# H5 register map
Vendor: Allwinner; Series: H5; File version: 0.1
CPU: 0, little endian, MPU, no FPU, 0 interrupt priority bits
Registers are 32-bit, read-write, reset 0x0 unless marked. A register's access mark holds for its fields unless they carry their own. Offsets are from the block's base; [hi:lo] are bit positions; {n}, {i} and the like mark numbered series.

## PIO
Base 0x01F02C00
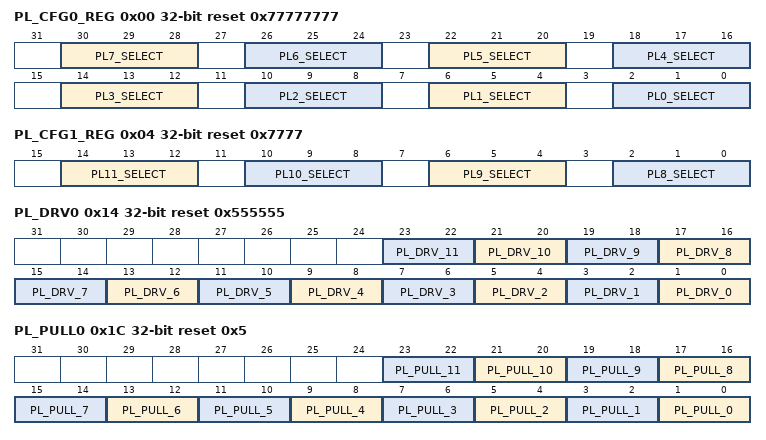
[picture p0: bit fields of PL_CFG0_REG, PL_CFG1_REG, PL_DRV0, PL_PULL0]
0x00 PL_CFG0_REG reset 0x77777777
  [30:28] PL7_SELECT — 000:Input 001:Output 010:S_JTAG_DI 011:Reserved 100:Reserved 101:Reserved 110:S_PL_EINT7 111:IO Disable
  [26:24] PL6_SELECT — 000:Input 001:Output 010:S_JTAG_DO 011:Reserved 100:Reserved 101:Reserved 110:S_PL_EINT6 111:IO Disable
  [22:20] PL5_SELECT — 000:Input 001:Output 010:S_JTAG_CK 011:Reserved 100:Reserved 101:Reserved 110:S_PL_EINT5 111:IO Disable
  [18:16] PL4_SELECT — 000:Input 001:Output 010:S_JTAG_MS 011:Reserved 100:Reserved 101:Reserved 110:S_PL_EINT4 111:IO Disable
  [14:12] PL3_SELECT — 000:Input 001:Output 010:S_UART_RX 011:Reserved 100:Reserved 101:Reserved 110:S_PL_EINT3 111:IO Disable
  [10:8] PL2_SELECT — 000:Input 001:Output 010:S_UART_TX 011:Reserved 100:Reserved 101:Reserved 110:S_PL_EINT2 111:IO Disable
  [6:4] PL1_SELECT — 000:Input 001:Output 010:S_TWI_SDA 011:Reserved 100:Reserved 101:Reserved 110:S_PL_EINT1 111:IO Disable
  [2:0] PL0_SELECT — 000:Input 001:Output 010:S_TWI_SCK 011:Reserved 100:Reserved 101:Reserved 110:S_PL_EINT0 111:IO Disable
0x04 PL_CFG1_REG reset 0x7777
  [14:12] PL11_SELECT — 000:Input 001:Output 010:S_CIR_RX 011:Reserved 100:Reserved 101:Reserved 110:S_PL_EINT11 111:IO Disable
  [10:8] PL10_SELECT — 000:Input 001:Output 010:S_PWM 011:Reserved 100:Reserved 101:Reserved 110:S_PL_EINT10 111:IO Disable
  [6:4] PL9_SELECT — 000:Input 001:Output 010:Reserved 011:Reserved 100:Reserved 101:Reserved 110:S_PL_EINT9 111:IO Disable
  [2:0] PL8_SELECT — 000:Input 001:Output 010:Reserved 011:Reserved 100:Reserved 101:Reserved 110:S_PL_EINT8 111:IO Disable
0x08 PL_CFG2_REG reset not defined
0x0C PL_CFG3_REG reset not defined
0x10 PL_DATA_REG
  [11:0] PL_DAT — If the port is configured as input, the corresponding bit is the pin state. If the port is configured as output, the pin state is the same as the corresponding bit. The read bit value is the value setup by software. If the port is configured as functional pin, the undefined value will be read.
0x14 PL_DRV0 reset 0x555555 — Port L Multi-Driving Register 0
  [2n+1:2n] PL_DRV_{n} (n=0..11) — PL[n] Multi-Driving Select (n = 0~11) 00: Level 0 01: Level 1 10: Level 2 11: Level 3
0x18 PL_DRV1 reset not defined — Port L Multi-Driving Register 1
0x1C PL_PULL0 reset 0x5
  [2n+1:2n] PL_PULL_{n} (n=0..11) — PL[n] Pull-up/down Select (n = 0~11) 00: Pull-up/down disable 01: Pull-up 10: Pull-down 11: Reserved
0x20 PL_PULL1 reset not defined
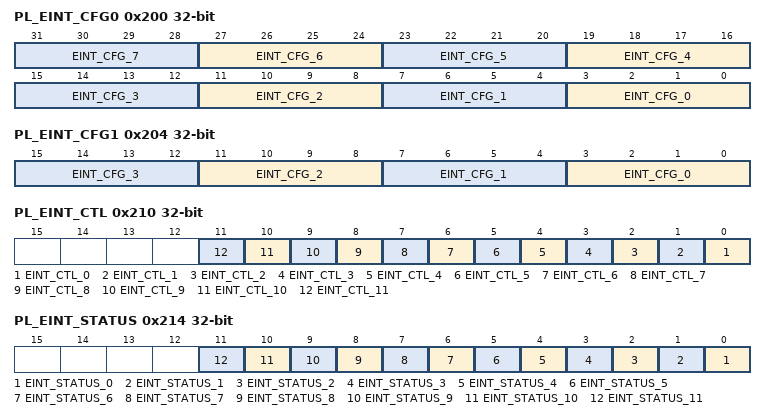
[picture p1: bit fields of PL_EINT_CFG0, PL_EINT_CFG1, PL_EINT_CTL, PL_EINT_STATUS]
0x200 PL_EINT_CFG0
  [4n+3:4n] EINT_CFG_{n} (n=0..7) — External INTn Mode (n = 0~7) 0000: Positive Edge 0001: Negative Edge 0010: High Level 0011: Low Level 0100: Double Edge (Positive/ Negative) Others: Reserved
0x204 PL_EINT_CFG1
  [4n+3:4n] EINT_CFG_{n} (n=0..3) — External INTn Mode (n = 8~11) 0000: Positive Edge 0001: Negative Edge 0010: High Level 0011: Low Level 0100: Double Edge (Positive/ Negative) Others: Reserved
0x208 PL_EINT_CFG2 reset not defined
0x20C PL_EINT_CFG3 reset not defined
0x210 PL_EINT_CTL
  [n] EINT_CTL_{n} (n=0..11) — External INTn Enable (n = 0~11) 0: Disable 1: Enable
0x214 PL_EINT_STATUS
  [n] EINT_STATUS_{n} (n=0..11) — External INTn Pending Bit (n = 0~11) 0: No IRQ pending 1: IRQ pending W ite to lea
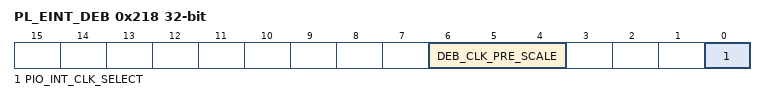
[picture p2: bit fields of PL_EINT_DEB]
0x218 PL_EINT_DEB
  [6:4] DEB_CLK_PRE_SCALE — Debounce Clock Pre-scale n The selected clock source is prescaled by 2^n.
  [0] PIO_INT_CLK_SELECT — PIO Interrupt Clock Select 0: LOSC 32KHz 1: HOSC 24MHz
    0=LOSC (LOSC 32KHz); 1=HOSC (HOSC 24MHz)

## PWM
Base 0x01C21400
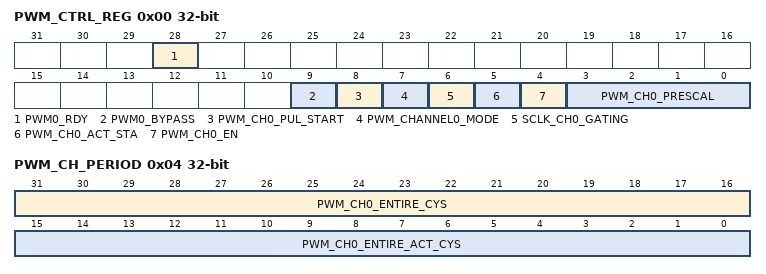
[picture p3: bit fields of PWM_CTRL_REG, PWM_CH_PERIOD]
0x00 PWM_CTRL_REG
  [28] PWM0_RDY ro — PWM0 Period Register Ready. 0: PWM0 period register is ready to write 1: PWM0 period register is busy.
    0=ready (PWM0 period register is ready to write); 1=busy (PWM0 period register is busy.)
  [9] PWM0_BYPASS — PWM CH0 Bypass Enable. If the bit is set to 1, PWM0 output is OSC24MHz. 0: Disable 1: Enable
    0=Disable; 1=Enable
  [8] PWM_CH0_PUL_START — PWM Channel 0 Pulse Output Start. 0: No effect 1: Output 1 pulse. The pulse width should be set by the bit[15:0] of PWM Channel Period Register ,and the pulse state should be set by PWM Channel 0 Active State . After the pulse is finished, the bit will be cleared automatically.
    0=No_effect; 1=Output 1 pulse. The pulse width should be set by the bit[15:0] of PWM Channel Period Register ,and the pulse state should be set by PWM Channel 0 Active State . After the pulse is finished, the bit will be cleared automatically.
  [7] PWM_CHANNEL0_MODE — 0: Cycle mode 1: Pulse mode.
    0=Cycle_mode; 1=Pulse mode
  [6] SCLK_CH0_GATING — Gating the Special Clock for PWM0 0: Mask 1: Pass
    0=Mask; 1=Pass
  [5] PWM_CH0_ACT_STA — PWM Channel 0 Active State. 0: Low Level 1: High Level.
    0=Low_Level; 1=High Level
  [4] PWM_CH0_EN — PWM Channel 0 Enable. 0: Disable 1: Enable.
    0=Disable; 1=Enable
  [3:0] PWM_CH0_PRESCAL — PWM Channel 0 Prescalar. These bits should be set before the PWM Channel 0 clock gate on. 0000: /120 0001: /180 0010: /240 0011: /360 0100: /480 0101: / 0110: / 0111: / 1000: /12k 1001: /24k 1010: /36k 1011: /48k 1100: /72k 1101: / 1110: / 1111: /1
    0=_slash_120 (/120); 1=_slash_180 (/180); 2=_slash_240 (/240); 3=_slash_360 (/360); 4=_slash_480 (/480); 8=_slash_12k (/12k); 9=_slash_24k (/24k); 10=_slash_36k (/36k); 11=_slash_48k (/48k); 12=_slash_72k (/72k); 15=_slash_1 (/1)
0x04 PWM_CH_PERIOD reset not defined — PWM Channel Period Register
  [31:16] PWM_CH0_ENTIRE_CYS — Number of the entire cycles in the PWM clock. 0 = 1 cycle 1 = 2 cycles ... N = N+1 cycles If the register need to be modified dynamically, the PCLK should be faster than the PWM CLK (PWM CLK = 24MHz/pre-scale).
  [15:0] PWM_CH0_ENTIRE_ACT_CYS — Number of the active cycles in the PWM clock. 0 = 0 cycle 1 = 1 cycles ... N = N cycles
